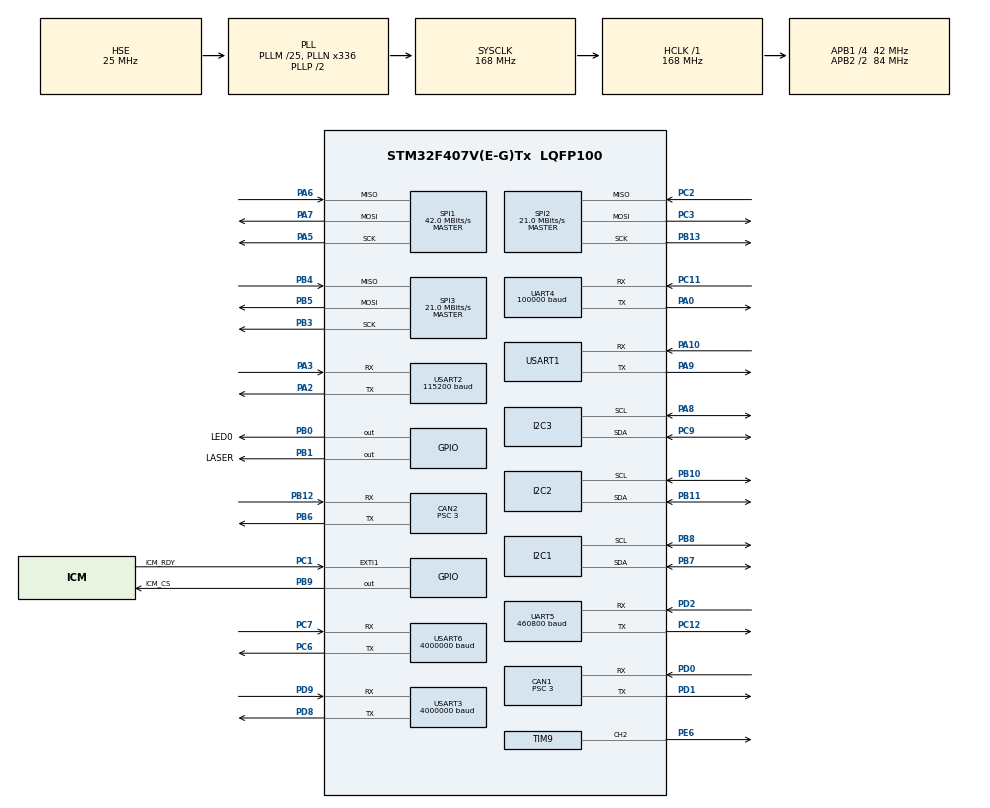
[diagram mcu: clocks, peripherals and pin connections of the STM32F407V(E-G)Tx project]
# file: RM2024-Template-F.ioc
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CAN1.ABOM=ENABLE
CAN1.BS1=CAN_BS1_9TQ
CAN1.BS2=CAN_BS2_4TQ
CAN1.CalculateBaudRate=1000000
CAN1.CalculateTimeBit=1000
CAN1.CalculateTimeQuantum=71.42857142857143
CAN1.Mode=CAN_MODE_NORMAL
CAN1.NART=DISABLE
CAN1.Prescaler=3
CAN2.ABOM=ENABLE
CAN2.BS1=CAN_BS1_9TQ
CAN2.BS2=CAN_BS2_4TQ
CAN2.CalculateBaudRate=1000000
CAN2.CalculateTimeBit=1000
CAN2.CalculateTimeQuantum=71.42857142857143
CAN2.Prescaler=3
Dma.Request0=UART5_RX
Dma.Request1=UART5_TX
Dma.Request2=UART4_RX
Dma.Request3=USART2_RX
Dma.Request4=USART6_RX
Dma.Request5=USART6_TX
Dma.Request6=SPI2_RX
Dma.Request7=SPI2_TX
Dma.SPI2_RX.6.Direction=DMA_PERIPH_TO_MEMORY
Dma.SPI2_RX.6.FIFOMode=DMA_FIFOMODE_DISABLE
Dma.SPI2_RX.6.Instance=DMA1_Stream3
Dma.SPI2_RX.6.MemDataAlignment=DMA_MDATAALIGN_BYTE
Dma.SPI2_RX.6.MemInc=DMA_MINC_ENABLE
Dma.SPI2_RX.6.Mode=DMA_NORMAL
Dma.SPI2_RX.6.PeriphDataAlignment=DMA_PDATAALIGN_BYTE
Dma.SPI2_RX.6.PeriphInc=DMA_PINC_DISABLE
Dma.SPI2_RX.6.Priority=DMA_PRIORITY_HIGH
Dma.SPI2_TX.7.Direction=DMA_MEMORY_TO_PERIPH
Dma.SPI2_TX.7.FIFOMode=DMA_FIFOMODE_DISABLE
Dma.SPI2_TX.7.Instance=DMA1_Stream4
Dma.SPI2_TX.7.MemDataAlignment=DMA_MDATAALIGN_BYTE
Dma.SPI2_TX.7.MemInc=DMA_MINC_ENABLE
Dma.SPI2_TX.7.Mode=DMA_NORMAL
Dma.SPI2_TX.7.PeriphDataAlignment=DMA_PDATAALIGN_BYTE
Dma.SPI2_TX.7.PeriphInc=DMA_PINC_DISABLE
Dma.SPI2_TX.7.Priority=DMA_PRIORITY_HIGH
Dma.UART4_RX.2.Direction=DMA_PERIPH_TO_MEMORY
Dma.UART4_RX.2.FIFOMode=DMA_FIFOMODE_DISABLE
Dma.UART4_RX.2.Instance=DMA1_Stream2
Dma.UART4_RX.2.MemDataAlignment=DMA_MDATAALIGN_BYTE
Dma.UART4_RX.2.MemInc=DMA_MINC_ENABLE
Dma.UART4_RX.2.Mode=DMA_NORMAL
Dma.UART4_RX.2.PeriphDataAlignment=DMA_PDATAALIGN_BYTE
Dma.UART4_RX.2.PeriphInc=DMA_PINC_DISABLE
Dma.UART4_RX.2.Priority=DMA_PRIORITY_HIGH
Dma.UART5_RX.0.Direction=DMA_PERIPH_TO_MEMORY
Dma.UART5_RX.0.FIFOMode=DMA_FIFOMODE_DISABLE
Dma.UART5_RX.0.Instance=DMA1_Stream0
Dma.UART5_RX.0.MemDataAlignment=DMA_MDATAALIGN_BYTE
Dma.UART5_RX.0.MemInc=DMA_MINC_ENABLE
Dma.UART5_RX.0.Mode=DMA_NORMAL
Dma.UART5_RX.0.PeriphDataAlignment=DMA_PDATAALIGN_BYTE
Dma.UART5_RX.0.PeriphInc=DMA_PINC_DISABLE
Dma.UART5_RX.0.Priority=DMA_PRIORITY_HIGH
Dma.UART5_TX.1.Direction=DMA_MEMORY_TO_PERIPH
Dma.UART5_TX.1.FIFOMode=DMA_FIFOMODE_DISABLE
Dma.UART5_TX.1.Instance=DMA1_Stream7
Dma.UART5_TX.1.MemDataAlignment=DMA_MDATAALIGN_BYTE
Dma.UART5_TX.1.MemInc=DMA_MINC_ENABLE
Dma.UART5_TX.1.Mode=DMA_NORMAL
Dma.UART5_TX.1.PeriphDataAlignment=DMA_PDATAALIGN_BYTE
Dma.UART5_TX.1.PeriphInc=DMA_PINC_DISABLE
Dma.UART5_TX.1.Priority=DMA_PRIORITY_HIGH
Dma.USART2_RX.3.Direction=DMA_PERIPH_TO_MEMORY
Dma.USART2_RX.3.FIFOMode=DMA_FIFOMODE_DISABLE
Dma.USART2_RX.3.Instance=DMA1_Stream5
Dma.USART2_RX.3.MemDataAlignment=DMA_MDATAALIGN_BYTE
Dma.USART2_RX.3.MemInc=DMA_MINC_ENABLE
Dma.USART2_RX.3.Mode=DMA_NORMAL
Dma.USART2_RX.3.PeriphDataAlignment=DMA_PDATAALIGN_BYTE
Dma.USART2_RX.3.PeriphInc=DMA_PINC_DISABLE
Dma.USART2_RX.3.Priority=DMA_PRIORITY_LOW
Dma.USART6_RX.4.Direction=DMA_PERIPH_TO_MEMORY
Dma.USART6_RX.4.FIFOMode=DMA_FIFOMODE_DISABLE
Dma.USART6_RX.4.Instance=DMA2_Stream1
Dma.USART6_RX.4.MemDataAlignment=DMA_MDATAALIGN_BYTE
Dma.USART6_RX.4.MemInc=DMA_MINC_ENABLE
Dma.USART6_RX.4.Mode=DMA_NORMAL
Dma.USART6_RX.4.PeriphDataAlignment=DMA_PDATAALIGN_BYTE
Dma.USART6_RX.4.PeriphInc=DMA_PINC_DISABLE
Dma.USART6_RX.4.Priority=DMA_PRIORITY_VERY_HIGH
Dma.USART6_TX.5.Direction=DMA_MEMORY_TO_PERIPH
Dma.USART6_TX.5.FIFOMode=DMA_FIFOMODE_DISABLE
Dma.USART6_TX.5.Instance=DMA2_Stream6
Dma.USART6_TX.5.MemDataAlignment=DMA_MDATAALIGN_BYTE
Dma.USART6_TX.5.MemInc=DMA_MINC_ENABLE
Dma.USART6_TX.5.Mode=DMA_NORMAL
Dma.USART6_TX.5.PeriphDataAlignment=DMA_PDATAALIGN_BYTE
Dma.USART6_TX.5.PeriphInc=DMA_PINC_DISABLE
Dma.USART6_TX.5.Priority=DMA_PRIORITY_VERY_HIGH
Mcu.Family=STM32F4
Mcu.Name=STM32F407V(E-G)Tx
Mcu.Package=LQFP100
NVIC.CAN1_RX0_IRQn=true\:10\:0\:true\:false\:true\:true\:true\:true
NVIC.CAN1_RX1_IRQn=true\:10\:0\:true\:false\:true\:true\:true\:true
NVIC.CAN1_TX_IRQn=true\:10\:0\:true\:false\:true\:true\:true\:true
NVIC.CAN2_RX0_IRQn=true\:10\:0\:true\:false\:true\:true\:true\:true
NVIC.CAN2_RX1_IRQn=true\:10\:0\:true\:false\:true\:true\:true\:true
NVIC.CAN2_TX_IRQn=true\:10\:0\:true\:false\:true\:true\:true\:true
NVIC.DMA1_Stream0_IRQn=true\:10\:0\:true\:false\:true\:false\:true\:true
NVIC.DMA1_Stream2_IRQn=true\:10\:0\:true\:false\:true\:false\:true\:true
NVIC.DMA1_Stream3_IRQn=true\:10\:0\:true\:false\:true\:false\:true\:true
NVIC.DMA1_Stream4_IRQn=true\:10\:0\:true\:false\:true\:false\:true\:true
NVIC.DMA1_Stream5_IRQn=true\:10\:0\:true\:false\:true\:false\:true\:true
NVIC.DMA1_Stream7_IRQn=true\:10\:0\:true\:false\:true\:false\:true\:true
NVIC.DMA2_Stream1_IRQn=true\:10\:0\:true\:false\:true\:false\:true\:true
NVIC.DMA2_Stream6_IRQn=true\:10\:0\:true\:false\:true\:false\:true\:true
NVIC.EXTI1_IRQn=true\:10\:0\:true\:false\:true\:true\:true\:true
NVIC.PriorityGroup=NVIC_PRIORITYGROUP_4
NVIC.SPI2_IRQn=true\:10\:0\:true\:false\:true\:true\:true\:true
NVIC.TIM7_IRQn=true\:15\:0\:false\:false\:true\:false\:true\:true
NVIC.TimeBase=TIM7_IRQn
NVIC.TimeBaseIP=TIM7
NVIC.UART4_IRQn=true\:10\:0\:true\:false\:true\:true\:true\:true
NVIC.UART5_IRQn=true\:10\:0\:true\:false\:true\:true\:true\:true
NVIC.USART2_IRQn=true\:10\:0\:true\:false\:true\:true\:true\:true
NVIC.USART6_IRQn=true\:10\:0\:true\:false\:true\:true\:true\:true
PA0-WKUP.Mode=Asynchronous
PA0-WKUP.Signal=UART4_TX
PA10.Mode=Asynchronous
PA10.Signal=USART1_RX
PA13.Mode=Serial_Wire
PA13.Signal=SYS_JTMS-SWDIO
PA14.Mode=Serial_Wire
PA14.Signal=SYS_JTCK-SWCLK
PA2.Mode=Asynchronous
PA2.Signal=USART2_TX
PA3.Mode=Asynchronous
PA3.Signal=USART2_RX
PA5.Mode=Full_Duplex_Master
PA5.Signal=SPI1_SCK
PA6.Mode=Full_Duplex_Master
PA6.Signal=SPI1_MISO
PA7.Mode=Full_Duplex_Master
PA7.Signal=SPI1_MOSI
PA8.Mode=I2C
PA8.Signal=I2C3_SCL
PA9.Mode=Asynchronous
PA9.Signal=USART1_TX
PB0.GPIO_Label=LED0
PB0.Signal=GPIO_Output
PB1.GPIO_Label=LASER
PB1.Signal=GPIO_Output
PB10.Mode=I2C
PB10.Signal=I2C2_SCL
PB11.Mode=I2C
PB11.Signal=I2C2_SDA
PB12.Mode=CAN_Activate
PB12.Signal=CAN2_RX
PB13.Mode=Full_Duplex_Master
PB13.Signal=SPI2_SCK
PB3.Mode=Full_Duplex_Master
PB3.Signal=SPI3_SCK
PB4.Mode=Full_Duplex_Master
PB4.Signal=SPI3_MISO
PB5.Mode=Full_Duplex_Master
PB5.Signal=SPI3_MOSI
PB6.Mode=CAN_Activate
PB6.Signal=CAN2_TX
PB7.Mode=I2C
PB7.Signal=I2C1_SDA
PB8.Mode=I2C
PB8.Signal=I2C1_SCL
PB9.GPIO_Label=ICM_CS
PB9.GPIO_Speed=GPIO_SPEED_FREQ_HIGH
PB9.PinState=GPIO_PIN_SET
PB9.Signal=GPIO_Output
PC1.GPIO_Label=ICM_RDY
PC1.Signal=GPXTI1
PC11.Mode=Asynchronous
PC11.Signal=UART4_RX
PC12.Mode=Asynchronous
PC12.Signal=UART5_TX
PC2.Mode=Full_Duplex_Master
PC2.Signal=SPI2_MISO
PC3.Mode=Full_Duplex_Master
PC3.Signal=SPI2_MOSI
PC6.GPIO_PuPd=GPIO_PULLUP
PC6.Mode=Asynchronous
PC6.Signal=USART6_TX
PC7.GPIO_PuPd=GPIO_PULLUP
PC7.Mode=Asynchronous
PC7.Signal=USART6_RX
PC9.Mode=I2C
PC9.Signal=I2C3_SDA
PD0.Mode=CAN_Activate
PD0.Signal=CAN1_RX
PD1.Mode=CAN_Activate
PD1.Signal=CAN1_TX
PD2.Mode=Asynchronous
PD2.Signal=UART5_RX
PD8.Mode=Asynchronous
PD8.Signal=USART3_TX
PD9.Mode=Asynchronous
PD9.Signal=USART3_RX
PE6.Signal=S_TIM9_CH2
PH0-OSC_IN.Mode=HSE-External-Oscillator
PH0-OSC_IN.Signal=RCC_OSC_IN
PH1-OSC_OUT.Mode=HSE-External-Oscillator
PH1-OSC_OUT.Signal=RCC_OSC_OUT
ProjectManager.HeapSize=0x200
ProjectManager.StackSize=0x400
ProjectManager.TargetToolchain=Makefile
RCC.48MHZClocksFreq_Value=56000000
RCC.AHBFreq_Value=168000000
RCC.APB1CLKDivider=RCC_HCLK_DIV4
RCC.APB1Freq_Value=42000000
RCC.APB1TimFreq_Value=84000000
RCC.APB2CLKDivider=RCC_HCLK_DIV2
RCC.APB2Freq_Value=84000000
RCC.APB2TimFreq_Value=168000000
RCC.CortexFreq_Value=168000000
RCC.HCLKFreq_Value=168000000
RCC.HSE_VALUE=25000000
RCC.HSI_VALUE=16000000
RCC.LSE_VALUE=32768
RCC.PLLM=25
RCC.PLLN=336
RCC.PLLQ=6
RCC.PLLSourceVirtual=RCC_PLLSOURCE_HSE
RCC.SYSCLKFreq_VALUE=168000000
RCC.SYSCLKSource=RCC_SYSCLKSOURCE_PLLCLK
RCC.VCOOutputFreq_Value=336000000
SH.S_TIM9_CH2.0=TIM9_CH2,PWM Generation2 CH2
SPI1.BaudRatePrescaler=SPI_BAUDRATEPRESCALER_2
SPI1.CalculateBaudRate=42.0 MBits/s
SPI1.Direction=SPI_DIRECTION_2LINES
SPI1.Mode=SPI_MODE_MASTER
SPI1.VirtualType=VM_MASTER
SPI2.BaudRatePrescaler=SPI_BAUDRATEPRESCALER_2
SPI2.CLKPhase=SPI_PHASE_2EDGE
SPI2.CLKPolarity=SPI_POLARITY_HIGH
SPI2.CalculateBaudRate=21.0 MBits/s
SPI2.DataSize=SPI_DATASIZE_8BIT
SPI2.Direction=SPI_DIRECTION_2LINES
SPI2.Mode=SPI_MODE_MASTER
SPI2.VirtualType=VM_MASTER
SPI3.BaudRatePrescaler=SPI_BAUDRATEPRESCALER_2
SPI3.CalculateBaudRate=21.0 MBits/s
SPI3.Direction=SPI_DIRECTION_2LINES
SPI3.Mode=SPI_MODE_MASTER
SPI3.VirtualType=VM_MASTER
STMicroelectronics.X-CUBE-ALGOBUILD.1.3.0.LibraryCcDSPOoLibraryJjDSPOoLibrary=true
TIM9.AutoReloadPreload=TIM_AUTORELOAD_PRELOAD_ENABLE
TIM9.Channel-PWM\ Generation2\ CH2=TIM_CHANNEL_2
TIM9.ClockDivision=TIM_CLOCKDIVISION_DIV1
TIM9.Period=5000
TIM9.Prescaler=13999
UART4.BaudRate=100000
UART4.Parity=PARITY_EVEN
UART4.VirtualMode=Asynchronous
UART4.WordLength=WORDLENGTH_9B
UART5.BaudRate=460800
UART5.VirtualMode=Asynchronous
USART1.VirtualMode=VM_ASYNC
USART2.BaudRate=115200
USART2.VirtualMode=VM_ASYNC
USART3.BaudRate=4000000
USART3.OverSampling=UART_OVERSAMPLING_8
USART3.VirtualMode=VM_ASYNC
USART6.BaudRate=4000000
USART6.VirtualMode=VM_ASYNC
VP_STMicroelectronics.X-CUBE-ALGOBUILD_VS_DSPOoLibraryJjLibrary_1.3.0_1.3.0.Mode=DSPOoLibraryJjLibrary
VP_SYS_VS_tim7.Mode=TIM7
board=custom

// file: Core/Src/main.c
/* USER CODE BEGIN Header */
/**
  ******************************************************************************
  * @file           : main.c
  * @brief          : Main program body
  ******************************************************************************
  * @attention
  *
  * Copyright (c) 2023 STMicroelectronics.
  * All rights reserved.
  *
  * This software is licensed under terms that can be found in the LICENSE file
  * in the root directory of this software component.
  * If no LICENSE file comes with this software, it is provided AS-IS.
  *
  ******************************************************************************
  */
/* USER CODE END Header */
#include "main.h"
#include "can.h"
#include "dma.h"
#include "i2c.h"
#include "spi.h"
#include "tim.h"
#include "usart.h"
#include "gpio.h"

/* USER CODE BEGIN Includes */

/* Includes ------------------------------------------------------------------*/

/* USER CODE END Includes */

void SystemClock_Config(void);

int main(void)
{

  /* MCU Configuration--------------------------------------------------------*/

  /* Reset of all peripherals, Initializes the Flash interface and the Systick. */
  HAL_Init();

  /* Configure the system clock */
  SystemClock_Config();

  /* Initialize all configured peripherals */
  MX_GPIO_Init();
  MX_DMA_Init();
  MX_CAN1_Init();
  MX_CAN2_Init();
  MX_SPI1_Init();
  MX_UART4_Init();
  MX_UART5_Init();
  MX_USART2_UART_Init();
  MX_USART1_UART_Init();
  MX_USART3_UART_Init();
  MX_USART6_UART_Init();
  MX_I2C1_Init();
  MX_I2C2_Init();
  MX_I2C3_Init();
  MX_SPI2_Init();
  MX_SPI3_Init();
  MX_TIM9_Init();

  /* Infinite loop */
  /* USER CODE BEGIN WHILE */
  extern void startRTOS(void);
  startRTOS();
  while (1)
  {
    /* USER CODE END WHILE */

  }
}

void SystemClock_Config(void)
{
  RCC_OscInitTypeDef RCC_OscInitStruct = {0};
  RCC_ClkInitTypeDef RCC_ClkInitStruct = {0};

  /** Configure the main internal regulator output voltage
  */
  __HAL_RCC_PWR_CLK_ENABLE();
  __HAL_PWR_VOLTAGESCALING_CONFIG(PWR_REGULATOR_VOLTAGE_SCALE1);

  /** Initializes the RCC Oscillators according to the specified parameters
  * in the RCC_OscInitTypeDef structure.
  */
  RCC_OscInitStruct.OscillatorType = RCC_OSCILLATORTYPE_HSE;
  RCC_OscInitStruct.HSEState = RCC_HSE_ON;
  RCC_OscInitStruct.PLL.PLLState = RCC_PLL_ON;
  RCC_OscInitStruct.PLL.PLLSource = RCC_PLLSOURCE_HSE;
  RCC_OscInitStruct.PLL.PLLM = 25;
  RCC_OscInitStruct.PLL.PLLN = 336;
  RCC_OscInitStruct.PLL.PLLP = RCC_PLLP_DIV2;
  RCC_OscInitStruct.PLL.PLLQ = 6;
  if (HAL_RCC_OscConfig(&RCC_OscInitStruct) != HAL_OK)
  {
    Error_Handler();
  }

  /** Initializes the CPU, AHB and APB buses clocks
  */
  RCC_ClkInitStruct.ClockType = RCC_CLOCKTYPE_HCLK|RCC_CLOCKTYPE_SYSCLK
                              |RCC_CLOCKTYPE_PCLK1|RCC_CLOCKTYPE_PCLK2;
  RCC_ClkInitStruct.SYSCLKSource = RCC_SYSCLKSOURCE_PLLCLK;
  RCC_ClkInitStruct.AHBCLKDivider = RCC_SYSCLK_DIV1;
  RCC_ClkInitStruct.APB1CLKDivider = RCC_HCLK_DIV4;
  RCC_ClkInitStruct.APB2CLKDivider = RCC_HCLK_DIV2;

  if (HAL_RCC_ClockConfig(&RCC_ClkInitStruct, FLASH_LATENCY_5) != HAL_OK)
  {
    Error_Handler();
  }
}

void HAL_TIM_PeriodElapsedCallback(TIM_HandleTypeDef *htim)
{
  if (htim->Instance == TIM7) {
    HAL_IncTick();
  }
}

void Error_Handler(void)
{
  __disable_irq();
  while (1)
  {
  }
}
